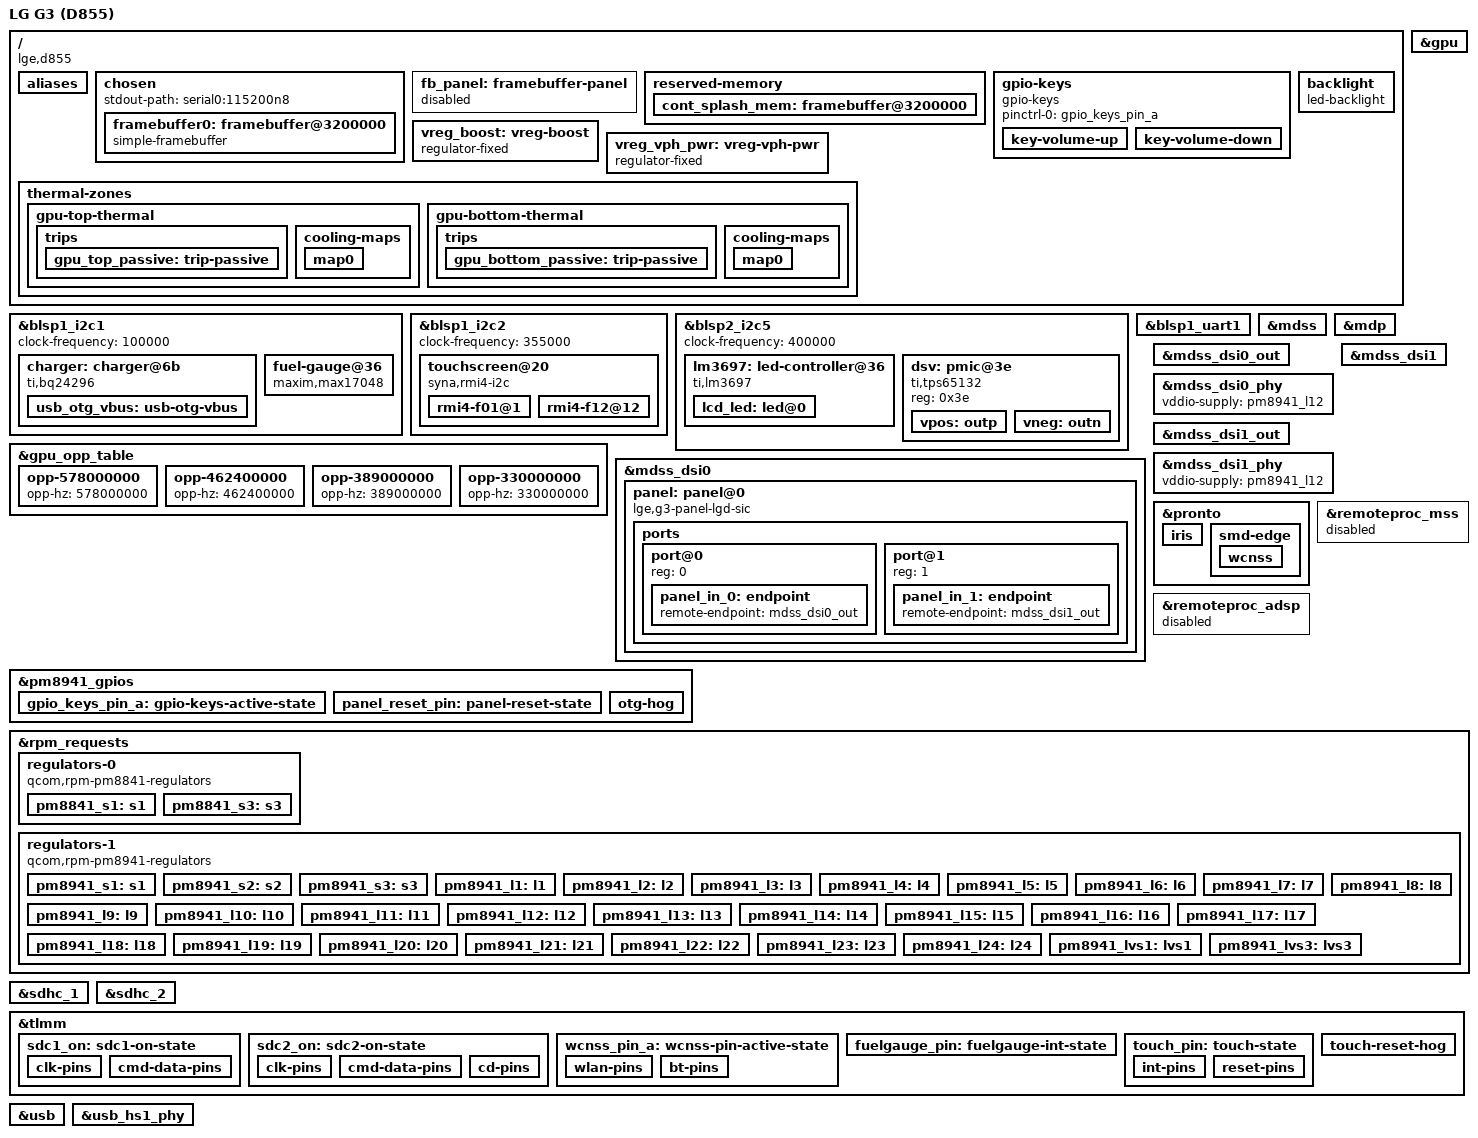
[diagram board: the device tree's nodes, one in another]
// SPDX-License-Identifier: GPL-2.0
/*
 * LG G3 (international, D855) — MSM8974AC (Snapdragon 801), PM8841 + PM8941
 *
 * Squelette de bring-up. Base : qcom-msm8974-lge-nexus5-hammerhead.dts
 * (même équipe LG, même architecture d'alimentation) et
 * qcom-msm8974pro-sony-xperia-shinano-common.dtsi (microSD sur SDHC2).
 * WiFi/BT : WCNSS Pronto + iris WCN3680 interne, comme
 * qcom-msm8974pro-oneplus-bacon.dts (les révisions de série rev_b+ n'ont
 * pas de BCM4339 : « WIFI doesn't use any sdcc from rev_b » dans le DTS
 * downstream, CONFIG_WCNSS_CORE_PRONTO=y et CONFIG_BT_HCISMD=y).
 *
 * Câblage relevé dans le noyau downstream LineageOS (lineage-18.1) :
 *   arch/arm/boot/dts/msm8974pro-g3-global_com/
 *   arch/arm/boot/dts/msm8974pro-lge-common/
 *   arch/arm/mach-msm/lge/8974ac-g3/board-8974-g3-*.c
 *
 * Les éléments marqués TODO ne sont pas encore validés sur le matériel.
 */

/dts-v1/;

#include "qcom-msm8974pro.dtsi"
#include "pm8841.dtsi"
#include "pm8941.dtsi"
#include <dt-bindings/gpio/gpio.h>
#include <dt-bindings/input/input.h>
#include <dt-bindings/leds/common.h>
#include <dt-bindings/pinctrl/qcom,pmic-gpio.h>
#include <dt-bindings/thermal/thermal.h>

/ {
	model = "LG G3 (D855)";
	compatible = "lge,d855", "qcom,msm8974pro", "qcom,msm8974";
	chassis-type = "handset";

	/* downstream : qcom,msm-id = <194 118 0x10001> (ancien format 3 cellules) */
	qcom,msm-id = <194 0x10001>;

	aliases {
		mmc0 = &sdhc_1;		/* eMMC */
		mmc1 = &sdhc_2;		/* microSD */
		serial0 = &blsp1_uart1;
	};

	chosen {
		#address-cells = <1>;
		#size-cells = <1>;
		ranges;

		stdout-path = "serial0:115200n8";

		/*
		 * Image laissée par le bootloader LG (relevée avec mdp-dump) :
		 * un seul tampon 1440x2560 RGB888 à 0x03200000, stride 4320,
		 * lu par les pipes RGB0 et RGB1 (une moitié de 720 par lien DSI).
		 * Linux continue simplement à y écrire (simpledrm). Les horloges
		 * et alimentations du MDP restent allumées grâce à
		 * clk_ignore_unused / pd_ignore_unused / regulator_ignore_unused,
		 * la bande passante mémoire grâce au vote d'interconnect.
		 * Si le rouge et le bleu sont inversés : format = "b8g8r8"
		 * n'existe pas, le dire et on passera par un autre format.
		 */
		framebuffer0: framebuffer@3200000 {
			compatible = "simple-framebuffer";
			reg = <0x03200000 (1440 * 2560 * 3)>;
			memory-region = <&cont_splash_mem>;
			/*
			 * Votes de simpledrm (patch 0003) tant que le bootloader
			 * affiche :
			 * - « mem » : mémoire principale (BIMC) à pleine vitesse,
			 *   sur le chemin d'entrée du trafic multimédia
			 *   (BIMC_TO_MNOC ; AMPSS_M0 n'a pas de lien vers EBI dans
			 *   le driver) ;
			 * - « bus » : bus multimédia (MMSS NoC) au débit du
			 *   framebuffer seulement, soit les 100 MHz du bootloader
			 *   (voir &mmssnoc plus bas).
			 */
			interconnects = <&bimc BIMC_TO_MNOC &bimc BIMC_SLV_EBI_CH0>,
					<&mmssnoc MNOC_MAS_MDP_PORT0 &mmssnoc MNOC_TO_BIMC>;
			interconnect-names = "mem", "bus";
			/*
			 * Le chargement de msm (sonde MDSS/MDP/DSI, runtime PM)
			 * coupe le GDSC MDSS et les horloges du MDP bien avant le
			 * premier modeset : le flux vidéo s'arrête et l'image part
			 * en fantôme (test « module_blacklist », pkgrel 31), même
			 * avec pd_ignore_unused. simpledrm garde donc le domaine
			 * et les horloges du cœur MDSS jusqu'à ce que msm le
			 * remplace. mmcc doit être intégré au noyau (=y), sinon
			 * simpledrm attend le module.
			 */
			power-domains = <&mmcc MDSS_GDSC>;
			clocks = <&mmcc MDSS_AHB_CLK>,
				 <&mmcc MDSS_AXI_CLK>,
				 <&mmcc MDSS_MDP_CLK>,
				 <&mmcc MDSS_MDP_LUT_CLK>,
				 <&mmcc MDSS_VSYNC_CLK>,
				 <&mmcc MDSS_ESC0_CLK>,
				 <&mmcc MDSS_ESC1_CLK>;
			width = <1440>;
			height = <2560>;
			stride = <(1440 * 3)>;
			format = "r8g8b8";
			/*
			 * Taille physique (width-mm/height-mm) pour simpledrm : phoc
			 * en déduit l'échelle. Nœud désactivé exprès : la propriété
			 * « panel » crée un lien fw_devlink, et pointer le vrai
			 * panneau (DSI) retarderait simpledrm jusqu'à ~25 s.
			 */
			panel = <&fb_panel>;
		};
	};

	/* dimensions de l'écran pour simpledrm (voir chosen/framebuffer) */
	fb_panel: framebuffer-panel {
		width-mm = <68>;
		height-mm = <121>;
		status = "disabled";
	};

	reserved-memory {
		/* Tampon d'affichage du bootloader, à ne pas réutiliser */
		cont_splash_mem: framebuffer@3200000 {
			reg = <0x03200000 (1440 * 2560 * 3)>;
			no-map;
		};
	};

	gpio-keys {
		compatible = "gpio-keys";

		pinctrl-names = "default";
		pinctrl-0 = <&gpio_keys_pin_a>;

		key-volume-up {
			label = "volume_up";
			gpios = <&pm8941_gpios 2 GPIO_ACTIVE_LOW>;
			linux,input-type = <1>;
			linux,code = <KEY_VOLUMEUP>;
			debounce-interval = <15>;
		};

		key-volume-down {
			label = "volume_down";
			gpios = <&pm8941_gpios 3 GPIO_ACTIVE_LOW>;
			linux,input-type = <1>;
			linux,code = <KEY_VOLUMEDOWN>;
			debounce-interval = <15>;
		};
	};

	/* Le LM3697 expose une LED : led-backlight en fait un backlight pour le panel */
	backlight: backlight {
		compatible = "led-backlight";
		leds = <&lcd_led>;
		/*
		 * Courbe de luminosité d'Android (blmap du LM3697 dans
		 * msm8974pro-lge-panel.dtsi) : 256 niveaux vers les codes 11 bits
		 * du LM3697 en mappage linéaire, 1892 au maximum (pas 2047). Le
		 * curseur de luminosité se comporte ainsi comme sous Android.
		 * Niveau par défaut 242 (code 1599) : à peu près la luminosité
		 * du bootloader ; Android démarre à 177 (code 625).
		 */
		brightness-levels = <
			0 2 2 3 4 4 5 6 6 7 8 8
			9 10 10 11 12 12 13 14 14 15 16 16
			17 18 18 19 19 20 21 21 22 23 23 24
			25 25 26 27 27 28 29 29 30 31 31 32
			33 33 34 34 34 35 35 35 35 35 35 36
			36 36 36 37 38 39 40 40 41 42 43 44
			45 47 48 50 51 53 54 56 57 59 60 62
			64 67 69 71 73 75 78 80 82 85 89 92
			96 99 102 106 109 113 116 120 123 127 131 134
			138 141 145 149 152 156 161 167 172 178 183 189
			194 200 205 210 215 220 225 230 235 239 244 249
			254 259 264 271 277 284 291 297 304 311 317 324
			332 340 348 356 364 371 379 387 395 403 411 420
			429 438 447 457 466 475 484 493 502 511 520 529
			538 547 555 564 573 582 591 600 612 625 637 650
			662 675 687 700 712 725 737 750 762 775 788 800
			813 825 838 851 863 876 888 901 913 926 938 951
			963 976 990 1004 1018 1032 1046 1060 1074 1088 1116 1124
			1130 1146 1163 1179 1196 1212 1228 1245 1261 1278 1294 1312
			1331 1349 1368 1386 1404 1423 1441 1460 1478 1498 1518 1539
			1559 1579 1599 1619 1640 1660 1680 1704 1727 1751 1774 1798
			1821 1845 1868 1892>;
		default-brightness-level = <242>;
		status = "okay";
	};

	/* Boost "bb_boost" piloté par PM8941 GPIO21 (identique au Nexus 5) */
	vreg_boost: vreg-boost {
		compatible = "regulator-fixed";

		regulator-name = "vreg-boost";
		regulator-min-microvolt = <3150000>;
		regulator-max-microvolt = <3150000>;

		regulator-always-on;
		regulator-boot-on;

		gpio = <&pm8941_gpios 21 GPIO_ACTIVE_HIGH>;
		enable-active-high;

		pinctrl-names = "default";
		pinctrl-0 = <&boost_bypass_n_pin>;
	};

	vreg_vph_pwr: vreg-vph-pwr {
		compatible = "regulator-fixed";
		regulator-name = "vph-pwr";

		regulator-min-microvolt = <3600000>;
		regulator-max-microvolt = <3600000>;

		regulator-always-on;
	};

};

/* Chargeur bq24296 + jauge MAX17048 (même bus et mêmes IRQ que le Nexus 5) */
&blsp1_i2c1 {
	status = "okay";
	clock-frequency = <100000>;

	charger: charger@6b {
		compatible = "ti,bq24296";
		reg = <0x6b>;
		/* EXT_CHG_INT = PM8941 GPIO22 */
		interrupts-extended = <&spmi_bus 0 0xd5 0 IRQ_TYPE_EDGE_FALLING>;

		omit-battery-class;

		usb_otg_vbus: usb-otg-vbus { };
	};

	fuel-gauge@36 {
		compatible = "maxim,max17048";
		reg = <0x36>;

		/* TODO : rcomp downstream = 103 (cellule LGC) / 55 (TCD) */
		maxim,double-soc;
		maxim,rcomp = /bits/ 8 <103>;

		interrupts-extended = <&tlmm 9 IRQ_TYPE_LEVEL_LOW>;

		pinctrl-names = "default";
		pinctrl-0 = <&fuelgauge_pin>;

		maxim,alert-low-soc-level = <2>;
	};
};

/* Tactile Synaptics S3528 (RMI4, F12) */
&blsp1_i2c2 {
	status = "okay";
	clock-frequency = <355000>;

	touchscreen@20 {
		compatible = "syna,rmi4-i2c";
		reg = <0x20>;

		interrupts-extended = <&tlmm 73 IRQ_TYPE_EDGE_FALLING>;
		vdd-supply = <&pm8941_l22>;
		vio-supply = <&pm8941_lvs3>;
		/* downstream : reset_delay = 10 ms ; marge pour le démarrage */
		syna,startup-delay-ms = <100>;

		pinctrl-names = "default";
		pinctrl-0 = <&touch_pin>;

		#address-cells = <1>;
		#size-cells = <0>;

		rmi4-f01@1 {
			reg = <0x1>;
			syna,nosleep-mode = <1>;
		};

		rmi4-f12@12 {
			reg = <0x12>;
			syna,sensor-type = <1>;
		};
	};
};

/*
 * Rétroéclairage LM3697 (0x36, HWEN = TLMM 91) et alimentation panel
 * TPS65132 (0x3e, DSV_EN = TLMM 56 / 100). Désactivé tant que l'affichage
 * passe par le framebuffer du bootloader : Linux ne doit pas toucher à ces
 * alimentations (sinon écran rose, voir README).
 */
&blsp2_i2c5 {
	status = "okay";
	clock-frequency = <400000>;

	lm3697: led-controller@36 {
		compatible = "ti,lm3697";
		reg = <0x36>;

		enable-gpios = <&tlmm 91 GPIO_ACTIVE_HIGH>;

		/*
		 * OVP du convertisseur à 24 V, comme le pilote LG (registre 0x1a =
		 * 0x02, patch noyau 0008). Avec les 16 V par défaut, le
		 * convertisseur reste en protection : pas de rétroéclairage.
		 */
		ti,ovp-microvolt = <24000000>;

		#address-cells = <1>;
		#size-cells = <0>;

		lcd_led: led@0 {
			reg = <0>;
			led-sources = <0 1>;	/* HVLED1 + HVLED2 (rev >= c) */
			ti,brightness-resolution = <2047>;
			/* mappage linéaire (patch noyau 0008) : l'exponentiel est trop sombre */
			ti,linear-mapping-mode;
			label = "lcd-backlight";
		};
	};

	/*
	 * VSP/VSN du panneau. Le schéma nomme les rails +5V5_DDVDH /
	 * -5V5_DDVDL, mais le pilote LG programme ±5,0 V (tps65132.c :
	 * TPS65132_VREG_LV_50 = 0x0a à l'allumage) et le bootloader laisse
	 * 5,0 V lui aussi. À 5,5 V, le panneau était suralimenté de 10 %.
	 */
	dsv: pmic@3e {
		compatible = "ti,tps65132";
		reg = <0x3e>;

		vpos: outp {
			regulator-name = "lcd-vpos";
			regulator-min-microvolt = <5000000>;
			regulator-max-microvolt = <5000000>;
			enable-gpios = <&tlmm 56 GPIO_ACTIVE_HIGH>;
		};

		vneg: outn {
			regulator-name = "lcd-vneg";
			regulator-min-microvolt = <5000000>;
			regulator-max-microvolt = <5000000>;
			enable-gpios = <&tlmm 100 GPIO_ACTIVE_HIGH>;
		};
	};
};

/* UART de debug (points de test, non câblé en externe) */
&blsp1_uart1 {
	status = "okay";
};

/*
 * Affichage : panel LGD SIC 1440x2560 vidéo, en DSI couplé (« bonded ») :
 * moitié gauche sur DSI0, moitié droite sur DSI1, 720x2560 et 4 lanes
 * chacun, commandes envoyées sur les deux liens. Driver :
 * panel-lge-g3-lgd-sic (patch 0002 du paquet noyau).
 *
 * Côté MDP5 : « split display » (patch noyau 0006), comme le bootloader :
 * CTL0/LM0/INTF1 pour la moitié gauche, CTL1/LM1/INTF2 pour la droite,
 * INTF2 synchronisé sur INTF1 (SPLIT_DPL). Le framebuffer du bootloader
 * (simpledrm) sert de console jusqu'à ce que msm prenne la main.
 *
 * Câblage confirmé par le manuel de service (pages 216, 224, 235) : reset
 * PM8941 GPIO 19, IOVCC L12, VSP/VSN TPS65132 (GPIO 56/100), rétroéclairage
 * LM3697 (GPIO 91), tous deux sur l'I2C commun (BLSP11 = blsp2_i2c5).
 */
/*
 * GPU Adreno 330, lié au pilote d'affichage msm.
 * - pas d'IOMMU GPU décrite pour la MSM8974 : msm.allow_vram_carveout=1 ;
 * - interconnects du dtsi conservés : le vote du GPU (fréquence max x 8
 *   octets) monte le bus multimédia de 100 à 291,75 MHz, voir &mmssnoc ;
 * - fréquences d'Android pour la MSM8974Pro-AC (msm8974pro.dtsi LG :
 *   578 / 462,4 / 389 / 330 / 200 / 27 MHz). La source d'horloge du GPU
 *   (gfx3d_clk_src) est gérée par le RPM, tension du rail comprise : le
 *   noyau ne demande qu'une fréquence, comme le pilote kgsl d'Android.
 *   Le dtsi en amont s'arrête aux 320 MHz de la MSM8974 d'origine ;
 * - #cooling-cells : le GPU est bridé par les zones thermiques gpu-top /
 *   gpu-bottom plus bas (CONFIG_DEVFREQ_THERMAL).
 */
&gpu {
	#cooling-cells = <2>;

	status = "okay";
};

/*
 * Bridage thermique du GPU : dès 80 °C sur l'un de ses deux capteurs, le
 * noyau baisse sa fréquence maximale pas à pas (Android le fait depuis
 * l'espace utilisateur, thermal-engine). Le seuil « hot » à 90 °C du dtsi
 * reste en place.
 */
/ {
	thermal-zones {
		gpu-top-thermal {
			trips {
				gpu_top_passive: trip-passive {
					temperature = <80000>;
					hysteresis = <2000>;
					type = "passive";
				};
			};

			cooling-maps {
				map0 {
					trip = <&gpu_top_passive>;
					cooling-device = <&gpu THERMAL_NO_LIMIT THERMAL_NO_LIMIT>;
				};
			};
		};

		gpu-bottom-thermal {
			trips {
				gpu_bottom_passive: trip-passive {
					temperature = <80000>;
					hysteresis = <2000>;
					type = "passive";
				};
			};

			cooling-maps {
				map0 {
					trip = <&gpu_bottom_passive>;
					cooling-device = <&gpu THERMAL_NO_LIMIT THERMAL_NO_LIMIT>;
				};
			};
		};
	};
};

&gpu_opp_table {
	/delete-node/ opp-320000000;

	opp-578000000 {
		opp-hz = /bits/ 64 <578000000>;
	};

	opp-462400000 {
		opp-hz = /bits/ 64 <462400000>;
	};

	opp-389000000 {
		opp-hz = /bits/ 64 <389000000>;
	};

	opp-330000000 {
		opp-hz = /bits/ 64 <330000000>;
	};
};

&mdss {
	status = "okay";
};

/*
 * Bande passante du MDP : mdp5 vote 6,4 Go/s en dur sur mdp0-mem. Par
 * mmssnoc, cela mettrait l'horloge AXI à 400 MHz (palier de tension
 * « turbo », que rien ne vote ici) : on garde le vote sur BIMC seul, qui
 * tient la mémoire à pleine vitesse, et c'est le GPU qui règle mmssnoc
 * (voir plus bas).
 */
&mdp {
	interconnects = <&bimc BIMC_TO_MNOC &bimc BIMC_SLV_EBI_CH0>;
	interconnect-names = "mdp0-mem";
};

/*
 * Bus multimédia (MMSS NoC), partagé par le MDP et le GPU. Le bootloader
 * laisse son horloge AXI à 100 MHz, soit 1,6 Go/s, dont l'affichage 1440p
 * prend déjà plus de la moitié : le GPU n'avait pas de quoi rendre 60
 * images par seconde. Android la monte à 400 MHz dès que l'écran est allumé.
 *
 * Son pilote d'interconnect part d'une bande passante nulle : au premier
 * vote ou au sync_state il règle l'horloge sur la somme des votes, et sans
 * vote suffisant le MDP passe en underflow (écran bleu). D'où :
 * - simpledrm vote dessus tant qu'il affiche (chemin « bus » du nœud
 *   framebuffer, patch 0003) : 1,3 Go/s, soit les 100 MHz du bootloader ;
 * - le GPU vote ensuite 4,6 Go/s en permanence (a3xx_gpu_init) : 291,75 MHz,
 *   le maximum du palier de tension « nominal » (personne ne vote la
 *   tension CX dans ce noyau, d'où le choix de ne pas viser 400 MHz) ;
 * - le MDP garde son vote sur BIMC seul (6,4 Go/s, mémoire à pleine vitesse).
 */

&mdss_dsi0 {
	vdda-supply = <&pm8941_l2>;
	vdd-supply = <&pm8941_lvs3>;
	vddio-supply = <&pm8941_l12>;

	qcom,dual-dsi-mode;
	qcom,master-dsi;
	/* commandes en broadcast sur les deux liens, comme LG (patch 0009) */
	qcom,sync-dual-dsi;

	status = "okay";

	panel: panel@0 {
		compatible = "lge,g3-panel-lgd-sic";
		/* 5,5" 16:9 */
		width-mm = <68>;
		height-mm = <121>;
		reg = <0>;

		/* IOVCC : L12 sur le schéma « RevB » (L10 sur l'ancien schéma bloc) */
		vdd-supply = <&pm8941_l12>;
		vsp-supply = <&vpos>;
		vsn-supply = <&vneg>;
		reset-gpios = <&pm8941_gpios 19 GPIO_ACTIVE_LOW>;

		backlight = <&backlight>;

		pinctrl-names = "default";
		pinctrl-0 = <&panel_reset_pin>;

		ports {
			#address-cells = <1>;
			#size-cells = <0>;

			port@0 {
				reg = <0>;
				panel_in_0: endpoint {
					remote-endpoint = <&mdss_dsi0_out>;
				};
			};

			port@1 {
				reg = <1>;
				panel_in_1: endpoint {
					remote-endpoint = <&mdss_dsi1_out>;
				};
			};
		};
	};
};

&mdss_dsi0_out {
	remote-endpoint = <&panel_in_0>;
	data-lanes = <0 1 2 3>;
};

&mdss_dsi0_phy {
	vddio-supply = <&pm8941_l12>;

	status = "okay";
};

&mdss_dsi1 {
	vdda-supply = <&pm8941_l2>;
	vdd-supply = <&pm8941_lvs3>;
	vddio-supply = <&pm8941_l12>;

	qcom,dual-dsi-mode;
	qcom,sync-dual-dsi;

	/*
	 * Interruption MDSS de DSI1 : bit 5 (MDSS_INTR_DSI1 en downstream).
	 * qcom-msm8974.dtsi met <4> aux deux contrôleurs : « Flags mismatch
	 * irq … dsi_isr » et DSI1 ne démarre pas. À corriger en amont.
	 */
	interrupts = <5>;

	/* En mode couplé, la PLL de DSI0 cadence les deux liens */
	assigned-clock-parents = <&mdss_dsi0_phy DSI_BYTE_PLL_CLK>,
				 <&mdss_dsi0_phy DSI_PIXEL_PLL_CLK>;

	status = "okay";
};

&mdss_dsi1_out {
	remote-endpoint = <&panel_in_1>;
	data-lanes = <0 1 2 3>;
};

&mdss_dsi1_phy {
	vddio-supply = <&pm8941_l12>;

	status = "okay";
};

&pm8941_gpios {
	gpio_keys_pin_a: gpio-keys-active-state {
		pins = "gpio2", "gpio3";
		function = "normal";

		bias-pull-up;
		power-source = <PM8941_GPIO_S3>;
	};

	/* Reset du panel (downstream : qcom,platform-reset-gpio) */
	panel_reset_pin: panel-reset-state {
		pins = "gpio19";
		function = "normal";

		bias-disable;
		power-source = <PM8941_GPIO_S3>;
		qcom,drive-strength = <PMIC_GPIO_STRENGTH_HIGH>;
	};

	/* PM8941 GPIO35 : OTG_EN du switch OVP (comme sur le Nexus 5) */
	otg-hog {
		gpio-hog;
		gpios = <35 GPIO_ACTIVE_HIGH>;
		output-high;
		line-name = "otg-gpio";
	};
};

/*
 * WiFi + Bluetooth : WCNSS (Pronto) + iris WCN3680. Alimentations identiques
 * au msm8974.dtsi downstream (qcom,wcnss-wlan@fb000000, non surchargé par le
 * G3). Firmware : wcnss.mdt/.bXX (partition modem) et WCNSS_qcom_wlan_nv.bin.
 */
&pronto {
	vddmx-supply = <&pm8841_s1>;
	vddpx-supply = <&pm8941_s3>;

	pinctrl-names = "default";
	pinctrl-0 = <&wcnss_pin_a>;

	firmware-name = "qcom/msm8974/lge/d855/wcnss.mdt";

	status = "okay";

	iris {
		vddxo-supply = <&pm8941_l6>;
		vddrfa-supply = <&pm8941_l11>;
		vddpa-supply = <&pm8941_l19>;
		vdddig-supply = <&pm8941_s3>;
	};

	smd-edge {
		qcom,remote-pid = <4>;
		label = "pronto";

		wcnss {
			firmware-name = "qcom/msm8974/lge/d855/WCNSS_qcom_wlan_nv.bin";
			status = "okay";
		};
	};
};

&remoteproc_adsp {
	/* TODO : nécessite adsp.mdt depuis la partition modem */
	status = "disabled";
};

&remoteproc_mss {
	mss-supply = <&pm8841_s3>;
	mx-supply = <&pm8841_s1>;
	pll-supply = <&pm8941_l12>;
	/* TODO : nécessite mba.mbn + modem.mdt depuis la partition modem */
	status = "disabled";
};

&rpm_requests {
	regulators-0 {
		compatible = "qcom,rpm-pm8841-regulators";

		pm8841_s1: s1 {
			regulator-min-microvolt = <675000>;
			regulator-max-microvolt = <1050000>;
		};

		pm8841_s3: s3 {
			regulator-min-microvolt = <1050000>;
			regulator-max-microvolt = <1050000>;
		};
	};

	/* Valeurs reprises du Nexus 5, TODO : comparer au downstream */
	regulators-1 {
		compatible = "qcom,rpm-pm8941-regulators";

		vdd_l1_l3-supply = <&pm8941_s1>;
		vdd_l2_lvs1_2_3-supply = <&pm8941_s3>;
		vdd_l4_l11-supply = <&pm8941_s1>;
		vdd_l5_l7-supply = <&pm8941_s2>;
		vdd_l6_l12_l14_l15-supply = <&pm8941_s2>;
		vdd_l8_l16_l18_l19-supply = <&vreg_vph_pwr>;
		vdd_l9_l10_l17_l22-supply = <&vreg_boost>;
		vdd_l13_l20_l23_l24-supply = <&vreg_boost>;
		vdd_l21-supply = <&vreg_boost>;

		pm8941_s1: s1 {
			regulator-min-microvolt = <1300000>;
			regulator-max-microvolt = <1300000>;
			regulator-always-on;
			regulator-boot-on;
		};

		pm8941_s2: s2 {
			regulator-min-microvolt = <2150000>;
			regulator-max-microvolt = <2150000>;
			regulator-boot-on;
		};

		pm8941_s3: s3 {
			regulator-min-microvolt = <1800000>;
			regulator-max-microvolt = <1800000>;
			regulator-always-on;
			regulator-boot-on;
		};

		pm8941_l1: l1 {
			regulator-min-microvolt = <1225000>;
			regulator-max-microvolt = <1225000>;
			regulator-always-on;
			regulator-boot-on;
		};

		pm8941_l2: l2 {
			regulator-min-microvolt = <1200000>;
			regulator-max-microvolt = <1200000>;
		};

		pm8941_l3: l3 {
			regulator-min-microvolt = <1225000>;
			regulator-max-microvolt = <1225000>;
		};

		pm8941_l4: l4 {
			regulator-min-microvolt = <1225000>;
			regulator-max-microvolt = <1225000>;
		};

		pm8941_l5: l5 {
			regulator-min-microvolt = <1800000>;
			regulator-max-microvolt = <1800000>;
		};

		pm8941_l6: l6 {
			regulator-min-microvolt = <1800000>;
			regulator-max-microvolt = <1800000>;
			regulator-boot-on;
		};

		pm8941_l7: l7 {
			regulator-min-microvolt = <1800000>;
			regulator-max-microvolt = <1800000>;
			regulator-boot-on;
		};

		pm8941_l8: l8 {
			regulator-min-microvolt = <1800000>;
			regulator-max-microvolt = <1800000>;
		};

		pm8941_l9: l9 {
			regulator-min-microvolt = <1800000>;
			regulator-max-microvolt = <2950000>;
		};

		/*
		 * Alimentation « vdd » 1,8 V du panneau dans le DT LG
		 * (msm8974pro-lge-panel.dtsi : vdd-supply = <&pm8941_l10> sur
		 * mdss_dsi0/1), seul consommateur de L10 côté LG. Gardée allumée
		 * à 1,8 V comme le bootloader la laisse.
		 */
		pm8941_l10: l10 {
			regulator-min-microvolt = <1800000>;
			regulator-max-microvolt = <1800000>;
			regulator-always-on;
			regulator-boot-on;
			/* charge déclarée par LG (100 mA) : mode HPM, pas idle */
			regulator-system-load = <100000>;
			regulator-allow-set-load;
		};

		pm8941_l11: l11 {
			regulator-min-microvolt = <1300000>;
			regulator-max-microvolt = <1300000>;
		};

		pm8941_l12: l12 {
			regulator-min-microvolt = <1800000>;
			regulator-max-microvolt = <1800000>;
			regulator-always-on;
			regulator-boot-on;
		};

		/* microSD VQMMC (downstream : jusqu'à 22 mA) */
		pm8941_l13: l13 {
			regulator-min-microvolt = <1800000>;
			regulator-max-microvolt = <2950000>;
			regulator-system-load = <22000>;
			regulator-allow-set-load;
			regulator-boot-on;
		};

		pm8941_l14: l14 {
			regulator-min-microvolt = <1800000>;
			regulator-max-microvolt = <1800000>;
		};

		pm8941_l15: l15 {
			regulator-min-microvolt = <2050000>;
			regulator-max-microvolt = <2050000>;
		};

		pm8941_l16: l16 {
			regulator-min-microvolt = <2700000>;
			regulator-max-microvolt = <2700000>;
		};

		pm8941_l17: l17 {
			regulator-min-microvolt = <2850000>;
			regulator-max-microvolt = <2850000>;
		};

		pm8941_l18: l18 {
			regulator-min-microvolt = <2850000>;
			regulator-max-microvolt = <2850000>;
		};

		pm8941_l19: l19 {
			regulator-min-microvolt = <3000000>;
			regulator-max-microvolt = <3300000>;
		};

		/* eMMC VMMC */
		pm8941_l20: l20 {
			regulator-min-microvolt = <2950000>;
			regulator-max-microvolt = <2950000>;
			regulator-system-load = <200000>;
			regulator-allow-set-load;
			regulator-boot-on;
		};

		/*
		 * microSD VMMC (downstream : jusqu'à 800 mA). Sans vote de charge,
		 * le RPM peut laisser le LDO en mode basse consommation, trop
		 * faible pour une carte en cours d'initialisation. Même réglage
		 * que le Xperia Z3 et le Galaxy S5.
		 */
		pm8941_l21: l21 {
			regulator-min-microvolt = <2950000>;
			regulator-max-microvolt = <2950000>;
			regulator-system-load = <500000>;
			regulator-allow-set-load;
			regulator-boot-on;
		};

		/* Tactile : le downstream le fixe à 3,3 V */
		pm8941_l22: l22 {
			regulator-min-microvolt = <3300000>;
			regulator-max-microvolt = <3300000>;
		};

		pm8941_l23: l23 {
			regulator-min-microvolt = <3000000>;
			regulator-max-microvolt = <3000000>;
		};

		pm8941_l24: l24 {
			regulator-min-microvolt = <3075000>;
			regulator-max-microvolt = <3075000>;
			regulator-boot-on;
		};

		pm8941_lvs1: lvs1 {};
		pm8941_lvs3: lvs3 {};
	};
};

/* eMMC */
&sdhc_1 {
	status = "okay";

	vmmc-supply = <&pm8941_l20>;
	vqmmc-supply = <&pm8941_s3>;

	pinctrl-names = "default", "sleep";
	pinctrl-0 = <&sdc1_on>;
	pinctrl-1 = <&sdc1_off>;
};

/* microSD (rev_a1 et suivantes), détection carte TLMM 95 active basse */
&sdhc_2 {
	status = "okay";

	vmmc-supply = <&pm8941_l21>;
	vqmmc-supply = <&pm8941_l13>;

	cd-gpios = <&tlmm 95 GPIO_ACTIVE_LOW>;

	pinctrl-names = "default", "sleep";
	pinctrl-0 = <&sdc2_on>;
	pinctrl-1 = <&sdc2_off>;
};

&tlmm {
	sdc1_on: sdc1-on-state {
		clk-pins {
			pins = "sdc1_clk";
			drive-strength = <16>;
			bias-disable;
		};

		cmd-data-pins {
			pins = "sdc1_cmd", "sdc1_data";
			drive-strength = <10>;
			bias-pull-up;
		};
	};

	sdc2_on: sdc2-on-state {
		/*
		 * Downstream G3 : horloge réduite de 16 à 6 mA (« 16mA --> 6mA »
		 * dans qcom,pad-drv-on). À 16 mA les modes UHS échouent.
		 */
		clk-pins {
			pins = "sdc2_clk";
			drive-strength = <6>;
			bias-disable;
		};

		cmd-data-pins {
			pins = "sdc2_cmd", "sdc2_data";
			drive-strength = <10>;
			bias-pull-up;
		};

		cd-pins {
			pins = "gpio95";
			function = "gpio";
			drive-strength = <2>;
			bias-disable;
		};
	};

	/* downstream : gpios 36..40 de qcom,wcnss-wlan */
	wcnss_pin_a: wcnss-pin-active-state {
		wlan-pins {
			pins = "gpio36", "gpio37", "gpio38", "gpio39", "gpio40";
			function = "wlan";
			drive-strength = <6>;
			bias-pull-down;
		};

		bt-pins {
			pins = "gpio35", "gpio43", "gpio44";
			function = "bt";
			drive-strength = <2>;
			bias-pull-down;
		};
	};

	fuelgauge_pin: fuelgauge-int-state {
		pins = "gpio9";
		function = "gpio";
		drive-strength = <2>;
		bias-disable;
		input-enable;
	};

	touch_pin: touch-state {
		int-pins {
			pins = "gpio73";
			function = "gpio";
			drive-strength = <2>;
			bias-disable;
		};

		reset-pins {
			pins = "gpio8";
			function = "gpio";
			drive-strength = <2>;
			bias-disable;
		};
	};

	/*
	 * Reset du tactile (actif bas). Le driver RMI4 ne gère pas de GPIO de
	 * reset : on le maintient relâché (niveau haut), comme le downstream
	 * après la mise sous tension.
	 */
	touch-reset-hog {
		gpio-hog;
		gpios = <8 GPIO_ACTIVE_HIGH>;
		output-high;
		line-name = "touch-reset-n";
	};
};

&usb {
	status = "okay";

	phys = <&usb_hs1_phy>;
	phy-select = <&tcsr 0xb000 0>;

	extcon = <&charger>, <&usb_id>;
	vbus-supply = <&usb_otg_vbus>;

	hnp-disable;
	srp-disable;
	adp-disable;
};

&usb_hs1_phy {
	status = "okay";

	v1p8-supply = <&pm8941_l6>;
	v3p3-supply = <&pm8941_l24>;

	qcom,init-seq = /bits/ 8 <0x1 0x64>;
};
